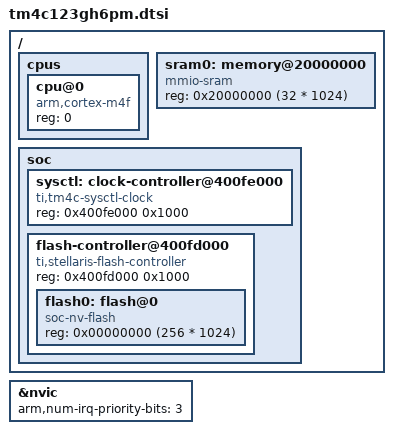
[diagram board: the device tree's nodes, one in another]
/* SPDX-License-Identifier: Apache-2.0 */

#include <arm/armv7-m.dtsi>

/ {
	cpus {
		#address-cells = <1>;
		#size-cells = <0>;

		cpu@0 {
			device_type = "cpu";
			compatible = "arm,cortex-m4f";
			reg = <0>;
		};
	};

	sram0: memory@20000000 {
		compatible = "mmio-sram";
		reg = <0x20000000 (32 * 1024)>;
	};

	soc {
		sysctl: clock-controller@400fe000 {
			compatible = "ti,tm4c-sysctl-clock";
			reg = <0x400fe000 0x1000>;
			#clock-cells = <1>;
		};

		flash-controller@400fd000 {
			compatible = "ti,stellaris-flash-controller";
			reg = <0x400fd000 0x1000>;
			#address-cells = <1>;
			#size-cells = <1>;

			flash0: flash@0 {
				compatible = "soc-nv-flash";
				reg = <0x00000000 (256 * 1024)>;
			};
		};
	};
};

&nvic {
	arm,num-irq-priority-bits = <3>;
};
